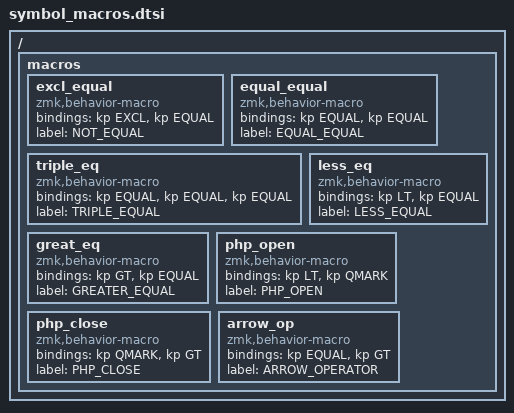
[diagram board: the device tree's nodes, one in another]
// =======================================
// === SYMBOL MACROS =====================
// =======================================
// This file defines macros for compound symbols and operators

/ {
    macros {
        // JavaScript/PHP comparison operators
        excl_equal: excl_equal {
            compatible = "zmk,behavior-macro";
            #binding-cells = <0>;
            bindings = <&kp EXCL &kp EQUAL>;
            label = "NOT_EQUAL";
        };

        equal_equal: equal_equal {
            compatible = "zmk,behavior-macro";
            #binding-cells = <0>;
            bindings = <&kp EQUAL &kp EQUAL>;
            label = "EQUAL_EQUAL";
        };

        triple_eq: triple_eq {
            compatible = "zmk,behavior-macro";
            #binding-cells = <0>;
            bindings = <&kp EQUAL &kp EQUAL &kp EQUAL>;
            label = "TRIPLE_EQUAL";
        };

        less_eq: less_eq {
            compatible = "zmk,behavior-macro";
            #binding-cells = <0>;
            bindings = <&kp LT &kp EQUAL>;
            label = "LESS_EQUAL";
        };

        great_eq: great_eq {
            compatible = "zmk,behavior-macro";
            #binding-cells = <0>;
            bindings = <&kp GT &kp EQUAL>;
            label = "GREATER_EQUAL";
        };

        // PHP tags
        php_open: php_open {
            compatible = "zmk,behavior-macro";
            #binding-cells = <0>;
            bindings = <&kp LT &kp QMARK>;
            label = "PHP_OPEN";
        };

        php_close: php_close {
            compatible = "zmk,behavior-macro";
            #binding-cells = <0>;
            bindings = <&kp QMARK &kp GT>;
            label = "PHP_CLOSE";
        };
        
        // Arrow operator for JavaScript/PHP
        arrow_op: arrow_op {
            compatible = "zmk,behavior-macro";
            #binding-cells = <0>;
            bindings = <&kp EQUAL &kp GT>;
            label = "ARROW_OPERATOR";
        };
    };
}; 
